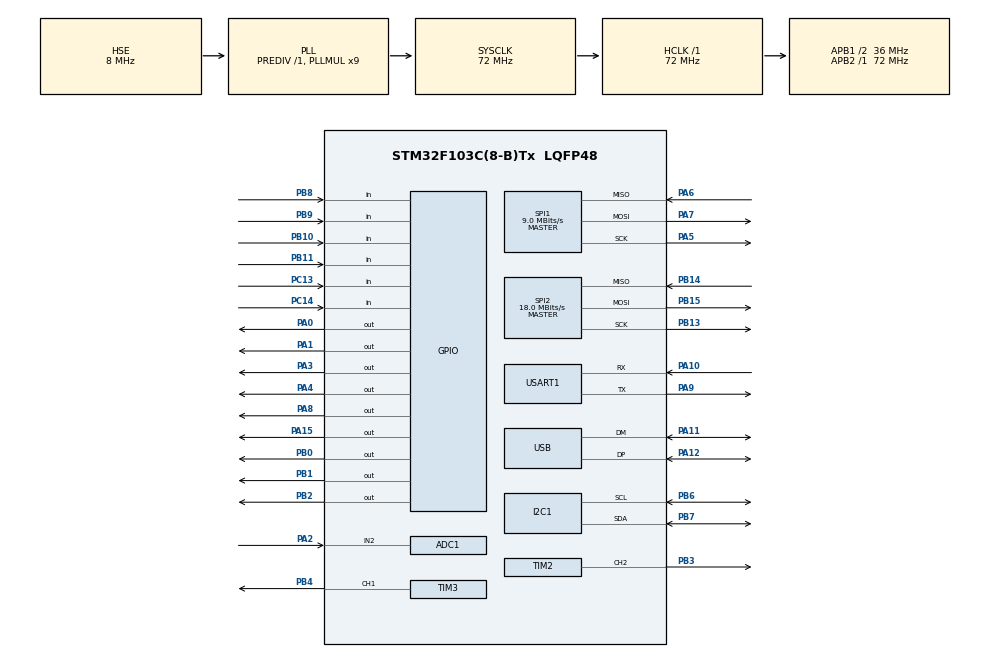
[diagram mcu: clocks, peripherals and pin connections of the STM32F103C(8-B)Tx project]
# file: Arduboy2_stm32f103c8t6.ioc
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ADC1.Channel-4\#ChannelRegularConversion=ADC_CHANNEL_2
ADC1.NbrOfConversionFlag=1
ADC1.Rank-4\#ChannelRegularConversion=1
ADC1.SamplingTime-4\#ChannelRegularConversion=ADC_SAMPLETIME_1CYCLE_5
ADC1.master=1
Mcu.Family=STM32F1
Mcu.Name=STM32F103C(8-B)Tx
Mcu.Package=LQFP48
NVIC.PriorityGroup=NVIC_PRIORITYGROUP_4
NVIC.TIM1_UP_IRQn=true\:0\:0\:false\:false\:true\:true\:true\:true
NVIC.TIM4_IRQn=true\:0\:0\:false\:false\:true\:true\:true\:true
PA0-WKUP.Signal=GPIO_Output
PA1.Signal=GPIO_Output
PA10.Mode=Asynchronous
PA10.Signal=USART1_RX
PA11.Mode=Device
PA11.Signal=USB_DM
PA12.Mode=Device
PA12.Signal=USB_DP
PA13.Mode=Serial_Wire
PA13.Signal=SYS_JTMS-SWDIO
PA14.Mode=Serial_Wire
PA14.Signal=SYS_JTCK-SWCLK
PA15.Signal=GPIO_Output
PA2.Signal=ADCx_IN2
PA3.Signal=GPIO_Output
PA4.Signal=GPIO_Output
PA5.Mode=Full_Duplex_Master
PA5.Signal=SPI1_SCK
PA6.Mode=Full_Duplex_Master
PA6.Signal=SPI1_MISO
PA7.Mode=Full_Duplex_Master
PA7.Signal=SPI1_MOSI
PA8.Signal=GPIO_Output
PA9.Mode=Asynchronous
PA9.Signal=USART1_TX
PB0.Signal=GPIO_Output
PB1.Signal=GPIO_Output
PB10.Signal=GPIO_Input
PB11.Signal=GPIO_Input
PB13.Mode=Full_Duplex_Master
PB13.Signal=SPI2_SCK
PB14.Mode=Full_Duplex_Master
PB14.Signal=SPI2_MISO
PB15.Mode=Full_Duplex_Master
PB15.Signal=SPI2_MOSI
PB2.Signal=GPIO_Output
PB3.Signal=S_TIM2_CH2
PB4.Signal=S_TIM3_CH1
PB6.Mode=I2C
PB6.Signal=I2C1_SCL
PB7.Mode=I2C
PB7.Signal=I2C1_SDA
PB8.Signal=GPIO_Input
PB9.Signal=GPIO_Input
PC13-TAMPER-RTC.Signal=GPIO_Input
PC14-OSC32_IN.Signal=GPIO_Input
PD0-OSC_IN.Mode=HSE-External-Oscillator
PD0-OSC_IN.Signal=RCC_OSC_IN
PD1-OSC_OUT.Mode=HSE-External-Oscillator
PD1-OSC_OUT.Signal=RCC_OSC_OUT
ProjectManager.HeapSize=0x200
ProjectManager.StackSize=0x400
ProjectManager.TargetToolchain=Makefile
RCC.ADCPresc=RCC_ADCPCLK2_DIV8
RCC.AHBFreq_Value=72000000
RCC.APB1CLKDivider=RCC_HCLK_DIV2
RCC.APB1Freq_Value=36000000
RCC.APB1TimFreq_Value=72000000
RCC.APB2Freq_Value=72000000
RCC.APB2TimFreq_Value=72000000
RCC.HCLKFreq_Value=72000000
RCC.PLLMUL=RCC_PLL_MUL9
RCC.SYSCLKFreq_VALUE=72000000
RCC.SYSCLKSource=RCC_SYSCLKSOURCE_PLLCLK
RCC.USBFreq_Value=48000000
RCC.USBPrescaler=RCC_USBCLKSOURCE_PLL_DIV1_5
SH.ADCx_IN2.0=ADC1_IN2,IN2
SH.S_TIM2_CH2.0=TIM2_CH2,PWM Generation2 CH2
SH.S_TIM3_CH1.0=TIM3_CH1,PWM Generation1 CH1
SPI1.BaudRatePrescaler=SPI_BAUDRATEPRESCALER_8
SPI1.CalculateBaudRate=9.0 MBits/s
SPI1.Direction=SPI_DIRECTION_2LINES
SPI1.Mode=SPI_MODE_MASTER
SPI1.VirtualType=VM_MASTER
SPI2.BaudRatePrescaler=SPI_BAUDRATEPRESCALER_2
SPI2.CalculateBaudRate=18.0 MBits/s
SPI2.Direction=SPI_DIRECTION_2LINES
SPI2.Mode=SPI_MODE_MASTER
SPI2.VirtualType=VM_MASTER
TIM1.AutoReloadPreload=TIM_AUTORELOAD_PRELOAD_ENABLE
TIM1.Period=62500
TIM1.Prescaler=1152-1
TIM2.AutoReloadPreload=TIM_AUTORELOAD_PRELOAD_ENABLE
TIM2.Channel-PWM\ Generation2\ CH2=TIM_CHANNEL_2
TIM2.Period=500
TIM2.Prescaler=71
TIM3.AutoReloadPreload=TIM_AUTORELOAD_PRELOAD_ENABLE
TIM3.Channel-PWM\ Generation1\ CH1=TIM_CHANNEL_1
TIM3.Period=500
TIM3.Prescaler=71
TIM4.AutoReloadPreload=TIM_AUTORELOAD_PRELOAD_ENABLE
TIM4.Period=62500
TIM4.Prescaler=1152-1
USART1.VirtualMode=VM_ASYNC
VP_TIM1_VS_ClockSourceINT.Mode=Internal
VP_TIM2_VS_ClockSourceINT.Mode=Internal
VP_TIM3_VS_ClockSourceINT.Mode=Internal
VP_TIM4_VS_ClockSourceINT.Mode=Internal
board=custom

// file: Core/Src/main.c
/* USER CODE BEGIN Header */
/**
  ******************************************************************************
  * @file           : main.c
  * @brief          : Main program body
  ******************************************************************************
  * @attention
  *
  * Copyright (c) 2024 STMicroelectronics.
  * All rights reserved.
  *
  * This software is licensed under terms that can be found in the LICENSE file
  * in the root directory of this software component.
  * If no LICENSE file comes with this software, it is provided AS-IS.
  *
  ******************************************************************************
  */
/* USER CODE END Header */
#include "main.h"

/* USER CODE BEGIN Includes */
#include <stdio.h>
#include "Arduboy2_app.h"
/* USER CODE END Includes */

ADC_HandleTypeDef hadc1;

I2C_HandleTypeDef hi2c1;

SPI_HandleTypeDef hspi1;
SPI_HandleTypeDef hspi2;

TIM_HandleTypeDef htim1;
TIM_HandleTypeDef htim2;
TIM_HandleTypeDef htim3;
TIM_HandleTypeDef htim4;

UART_HandleTypeDef huart1;

PCD_HandleTypeDef hpcd_USB_FS;

void SystemClock_Config(void);
static void MX_GPIO_Init(void);
static void MX_SPI1_Init(void);
static void MX_USART1_UART_Init(void);
static void MX_USB_PCD_Init(void);
static void MX_I2C1_Init(void);
static void MX_SPI2_Init(void);
static void MX_TIM2_Init(void);
static void MX_ADC1_Init(void);
static void MX_TIM3_Init(void);
static void MX_TIM1_Init(void);
static void MX_TIM4_Init(void);

/* USER CODE BEGIN 0 */
int _write (int fd, char *pBuffer, int size)
{
    HAL_UART_Transmit(&huart1, (uint8_t *) pBuffer, size, 0xFFFF);
    return size;
}
/* USER CODE END 0 */

int main(void)
{

  /* MCU Configuration--------------------------------------------------------*/

  /* Reset of all peripherals, Initializes the Flash interface and the Systick. */
  HAL_Init();

  /* Configure the system clock */
  SystemClock_Config();

  /* Initialize all configured peripherals */
  MX_GPIO_Init();
  MX_SPI1_Init();
  MX_USART1_UART_Init();
  MX_USB_PCD_Init();
  MX_I2C1_Init();
  MX_SPI2_Init();
  MX_TIM2_Init();
  MX_ADC1_Init();
  MX_TIM3_Init();
  MX_TIM1_Init();
  MX_TIM4_Init();
  /* USER CODE BEGIN 2 */
  arduboy2_app_init();
  /* USER CODE END 2 */

  /* Infinite loop */
  while (1)
  {

    /* USER CODE BEGIN 3 */
    HAL_Delay(1000);
    // pwm = (pwm >= 500) ? 0 : (pwm + 50);
  }
  /* USER CODE END 3 */
}

void SystemClock_Config(void)
{
  RCC_OscInitTypeDef RCC_OscInitStruct = {0};
  RCC_ClkInitTypeDef RCC_ClkInitStruct = {0};
  RCC_PeriphCLKInitTypeDef PeriphClkInit = {0};

  /** Initializes the RCC Oscillators according to the specified parameters
  * in the RCC_OscInitTypeDef structure.
  */
  RCC_OscInitStruct.OscillatorType = RCC_OSCILLATORTYPE_HSE;
  RCC_OscInitStruct.HSEState = RCC_HSE_ON;
  RCC_OscInitStruct.HSEPredivValue = RCC_HSE_PREDIV_DIV1;
  RCC_OscInitStruct.HSIState = RCC_HSI_ON;
  RCC_OscInitStruct.PLL.PLLState = RCC_PLL_ON;
  RCC_OscInitStruct.PLL.PLLSource = RCC_PLLSOURCE_HSE;
  RCC_OscInitStruct.PLL.PLLMUL = RCC_PLL_MUL9;
  if (HAL_RCC_OscConfig(&RCC_OscInitStruct) != HAL_OK)
  {
    Error_Handler();
  }

  /** Initializes the CPU, AHB and APB buses clocks
  */
  RCC_ClkInitStruct.ClockType = RCC_CLOCKTYPE_HCLK|RCC_CLOCKTYPE_SYSCLK
                              |RCC_CLOCKTYPE_PCLK1|RCC_CLOCKTYPE_PCLK2;
  RCC_ClkInitStruct.SYSCLKSource = RCC_SYSCLKSOURCE_PLLCLK;
  RCC_ClkInitStruct.AHBCLKDivider = RCC_SYSCLK_DIV1;
  RCC_ClkInitStruct.APB1CLKDivider = RCC_HCLK_DIV2;
  RCC_ClkInitStruct.APB2CLKDivider = RCC_HCLK_DIV1;

  if (HAL_RCC_ClockConfig(&RCC_ClkInitStruct, FLASH_LATENCY_2) != HAL_OK)
  {
    Error_Handler();
  }
  PeriphClkInit.PeriphClockSelection = RCC_PERIPHCLK_ADC|RCC_PERIPHCLK_USB;
  PeriphClkInit.AdcClockSelection = RCC_ADCPCLK2_DIV8;
  PeriphClkInit.UsbClockSelection = RCC_USBCLKSOURCE_PLL_DIV1_5;
  if (HAL_RCCEx_PeriphCLKConfig(&PeriphClkInit) != HAL_OK)
  {
    Error_Handler();
  }
}

static void MX_ADC1_Init(void)
{

  ADC_ChannelConfTypeDef sConfig = {0};

  /** Common config
  */
  hadc1.Instance = ADC1;
  hadc1.Init.ScanConvMode = ADC_SCAN_DISABLE;
  hadc1.Init.ContinuousConvMode = DISABLE;
  hadc1.Init.DiscontinuousConvMode = DISABLE;
  hadc1.Init.ExternalTrigConv = ADC_SOFTWARE_START;
  hadc1.Init.DataAlign = ADC_DATAALIGN_RIGHT;
  hadc1.Init.NbrOfConversion = 1;
  if (HAL_ADC_Init(&hadc1) != HAL_OK)
  {
    Error_Handler();
  }

  /** Configure Regular Channel
  */
  sConfig.Channel = ADC_CHANNEL_2;
  sConfig.Rank = ADC_REGULAR_RANK_1;
  sConfig.SamplingTime = ADC_SAMPLETIME_1CYCLE_5;
  if (HAL_ADC_ConfigChannel(&hadc1, &sConfig) != HAL_OK)
  {
    Error_Handler();
  }

}

static void MX_I2C1_Init(void)
{

  hi2c1.Instance = I2C1;
  hi2c1.Init.ClockSpeed = 100000;
  hi2c1.Init.DutyCycle = I2C_DUTYCYCLE_2;
  hi2c1.Init.OwnAddress1 = 0;
  hi2c1.Init.AddressingMode = I2C_ADDRESSINGMODE_7BIT;
  hi2c1.Init.DualAddressMode = I2C_DUALADDRESS_DISABLE;
  hi2c1.Init.OwnAddress2 = 0;
  hi2c1.Init.GeneralCallMode = I2C_GENERALCALL_DISABLE;
  hi2c1.Init.NoStretchMode = I2C_NOSTRETCH_DISABLE;
  if (HAL_I2C_Init(&hi2c1) != HAL_OK)
  {
    Error_Handler();
  }

}

static void MX_SPI1_Init(void)
{

  /* SPI1 parameter configuration*/
  hspi1.Instance = SPI1;
  hspi1.Init.Mode = SPI_MODE_MASTER;
  hspi1.Init.Direction = SPI_DIRECTION_2LINES;
  hspi1.Init.DataSize = SPI_DATASIZE_8BIT;
  hspi1.Init.CLKPolarity = SPI_POLARITY_LOW;
  hspi1.Init.CLKPhase = SPI_PHASE_1EDGE;
  hspi1.Init.NSS = SPI_NSS_SOFT;
  hspi1.Init.BaudRatePrescaler = SPI_BAUDRATEPRESCALER_8;
  hspi1.Init.FirstBit = SPI_FIRSTBIT_MSB;
  hspi1.Init.TIMode = SPI_TIMODE_DISABLE;
  hspi1.Init.CRCCalculation = SPI_CRCCALCULATION_DISABLE;
  hspi1.Init.CRCPolynomial = 10;
  if (HAL_SPI_Init(&hspi1) != HAL_OK)
  {
    Error_Handler();
  }

}

static void MX_SPI2_Init(void)
{

  /* SPI2 parameter configuration*/
  hspi2.Instance = SPI2;
  hspi2.Init.Mode = SPI_MODE_MASTER;
  hspi2.Init.Direction = SPI_DIRECTION_2LINES;
  hspi2.Init.DataSize = SPI_DATASIZE_8BIT;
  hspi2.Init.CLKPolarity = SPI_POLARITY_LOW;
  hspi2.Init.CLKPhase = SPI_PHASE_1EDGE;
  hspi2.Init.NSS = SPI_NSS_SOFT;
  hspi2.Init.BaudRatePrescaler = SPI_BAUDRATEPRESCALER_2;
  hspi2.Init.FirstBit = SPI_FIRSTBIT_MSB;
  hspi2.Init.TIMode = SPI_TIMODE_DISABLE;
  hspi2.Init.CRCCalculation = SPI_CRCCALCULATION_DISABLE;
  hspi2.Init.CRCPolynomial = 10;
  if (HAL_SPI_Init(&hspi2) != HAL_OK)
  {
    Error_Handler();
  }

}

static void MX_TIM1_Init(void)
{

  TIM_ClockConfigTypeDef sClockSourceConfig = {0};
  TIM_MasterConfigTypeDef sMasterConfig = {0};

  htim1.Instance = TIM1;
  htim1.Init.Prescaler = 1152-1;
  htim1.Init.CounterMode = TIM_COUNTERMODE_UP;
  htim1.Init.Period = 62500;
  htim1.Init.ClockDivision = TIM_CLOCKDIVISION_DIV1;
  htim1.Init.RepetitionCounter = 0;
  htim1.Init.AutoReloadPreload = TIM_AUTORELOAD_PRELOAD_ENABLE;
  if (HAL_TIM_Base_Init(&htim1) != HAL_OK)
  {
    Error_Handler();
  }
  sClockSourceConfig.ClockSource = TIM_CLOCKSOURCE_INTERNAL;
  if (HAL_TIM_ConfigClockSource(&htim1, &sClockSourceConfig) != HAL_OK)
  {
    Error_Handler();
  }
  sMasterConfig.MasterOutputTrigger = TIM_TRGO_RESET;
  sMasterConfig.MasterSlaveMode = TIM_MASTERSLAVEMODE_DISABLE;
  if (HAL_TIMEx_MasterConfigSynchronization(&htim1, &sMasterConfig) != HAL_OK)
  {
    Error_Handler();
  }

}

static void MX_TIM2_Init(void)
{

  TIM_ClockConfigTypeDef sClockSourceConfig = {0};
  TIM_MasterConfigTypeDef sMasterConfig = {0};
  TIM_OC_InitTypeDef sConfigOC = {0};

  htim2.Instance = TIM2;
  htim2.Init.Prescaler = 71;
  htim2.Init.CounterMode = TIM_COUNTERMODE_UP;
  htim2.Init.Period = 500;
  htim2.Init.ClockDivision = TIM_CLOCKDIVISION_DIV1;
  htim2.Init.AutoReloadPreload = TIM_AUTORELOAD_PRELOAD_ENABLE;
  if (HAL_TIM_Base_Init(&htim2) != HAL_OK)
  {
    Error_Handler();
  }
  sClockSourceConfig.ClockSource = TIM_CLOCKSOURCE_INTERNAL;
  if (HAL_TIM_ConfigClockSource(&htim2, &sClockSourceConfig) != HAL_OK)
  {
    Error_Handler();
  }
  if (HAL_TIM_PWM_Init(&htim2) != HAL_OK)
  {
    Error_Handler();
  }
  sMasterConfig.MasterOutputTrigger = TIM_TRGO_RESET;
  sMasterConfig.MasterSlaveMode = TIM_MASTERSLAVEMODE_DISABLE;
  if (HAL_TIMEx_MasterConfigSynchronization(&htim2, &sMasterConfig) != HAL_OK)
  {
    Error_Handler();
  }
  sConfigOC.OCMode = TIM_OCMODE_PWM1;
  sConfigOC.Pulse = 0;
  sConfigOC.OCPolarity = TIM_OCPOLARITY_HIGH;
  sConfigOC.OCFastMode = TIM_OCFAST_DISABLE;
  if (HAL_TIM_PWM_ConfigChannel(&htim2, &sConfigOC, TIM_CHANNEL_2) != HAL_OK)
  {
    Error_Handler();
  }
  HAL_TIM_MspPostInit(&htim2);

}

static void MX_TIM3_Init(void)
{

  TIM_ClockConfigTypeDef sClockSourceConfig = {0};
  TIM_MasterConfigTypeDef sMasterConfig = {0};
  TIM_OC_InitTypeDef sConfigOC = {0};

  htim3.Instance = TIM3;
  htim3.Init.Prescaler = 71;
  htim3.Init.CounterMode = TIM_COUNTERMODE_UP;
  htim3.Init.Period = 500;
  htim3.Init.ClockDivision = TIM_CLOCKDIVISION_DIV1;
  htim3.Init.AutoReloadPreload = TIM_AUTORELOAD_PRELOAD_ENABLE;
  if (HAL_TIM_Base_Init(&htim3) != HAL_OK)
  {
    Error_Handler();
  }
  sClockSourceConfig.ClockSource = TIM_CLOCKSOURCE_INTERNAL;
  if (HAL_TIM_ConfigClockSource(&htim3, &sClockSourceConfig) != HAL_OK)
  {
    Error_Handler();
  }
  if (HAL_TIM_PWM_Init(&htim3) != HAL_OK)
  {
    Error_Handler();
  }
  sMasterConfig.MasterOutputTrigger = TIM_TRGO_RESET;
  sMasterConfig.MasterSlaveMode = TIM_MASTERSLAVEMODE_DISABLE;
  if (HAL_TIMEx_MasterConfigSynchronization(&htim3, &sMasterConfig) != HAL_OK)
  {
    Error_Handler();
  }
  sConfigOC.OCMode = TIM_OCMODE_PWM1;
  sConfigOC.Pulse = 0;
  sConfigOC.OCPolarity = TIM_OCPOLARITY_HIGH;
  sConfigOC.OCFastMode = TIM_OCFAST_DISABLE;
  if (HAL_TIM_PWM_ConfigChannel(&htim3, &sConfigOC, TIM_CHANNEL_1) != HAL_OK)
  {
    Error_Handler();
  }
  HAL_TIM_MspPostInit(&htim3);

}

static void MX_TIM4_Init(void)
{

  TIM_ClockConfigTypeDef sClockSourceConfig = {0};
  TIM_MasterConfigTypeDef sMasterConfig = {0};

  htim4.Instance = TIM4;
  htim4.Init.Prescaler = 1152-1;
  htim4.Init.CounterMode = TIM_COUNTERMODE_UP;
  htim4.Init.Period = 62500;
  htim4.Init.ClockDivision = TIM_CLOCKDIVISION_DIV1;
  htim4.Init.AutoReloadPreload = TIM_AUTORELOAD_PRELOAD_ENABLE;
  if (HAL_TIM_Base_Init(&htim4) != HAL_OK)
  {
    Error_Handler();
  }
  sClockSourceConfig.ClockSource = TIM_CLOCKSOURCE_INTERNAL;
  if (HAL_TIM_ConfigClockSource(&htim4, &sClockSourceConfig) != HAL_OK)
  {
    Error_Handler();
  }
  sMasterConfig.MasterOutputTrigger = TIM_TRGO_RESET;
  sMasterConfig.MasterSlaveMode = TIM_MASTERSLAVEMODE_DISABLE;
  if (HAL_TIMEx_MasterConfigSynchronization(&htim4, &sMasterConfig) != HAL_OK)
  {
    Error_Handler();
  }

}

static void MX_USART1_UART_Init(void)
{

  huart1.Instance = USART1;
  huart1.Init.BaudRate = 115200;
  huart1.Init.WordLength = UART_WORDLENGTH_8B;
  huart1.Init.StopBits = UART_STOPBITS_1;
  huart1.Init.Parity = UART_PARITY_NONE;
  huart1.Init.Mode = UART_MODE_TX_RX;
  huart1.Init.HwFlowCtl = UART_HWCONTROL_NONE;
  huart1.Init.OverSampling = UART_OVERSAMPLING_16;
  if (HAL_UART_Init(&huart1) != HAL_OK)
  {
    Error_Handler();
  }

}

static void MX_USB_PCD_Init(void)
{

  hpcd_USB_FS.Instance = USB;
  hpcd_USB_FS.Init.dev_endpoints = 8;
  hpcd_USB_FS.Init.speed = PCD_SPEED_FULL;
  hpcd_USB_FS.Init.low_power_enable = DISABLE;
  hpcd_USB_FS.Init.lpm_enable = DISABLE;
  hpcd_USB_FS.Init.battery_charging_enable = DISABLE;
  if (HAL_PCD_Init(&hpcd_USB_FS) != HAL_OK)
  {
    Error_Handler();
  }

}

static void MX_GPIO_Init(void)
{
  GPIO_InitTypeDef GPIO_InitStruct = {0};

  /* GPIO Ports Clock Enable */
  __HAL_RCC_GPIOC_CLK_ENABLE();
  __HAL_RCC_GPIOD_CLK_ENABLE();
  __HAL_RCC_GPIOA_CLK_ENABLE();
  __HAL_RCC_GPIOB_CLK_ENABLE();

  /*Configure GPIO pin Output Level */
  HAL_GPIO_WritePin(GPIOA, GPIO_PIN_0|GPIO_PIN_1|GPIO_PIN_3|GPIO_PIN_4
                          |GPIO_PIN_8|GPIO_PIN_15, GPIO_PIN_RESET);

  /*Configure GPIO pin Output Level */
  HAL_GPIO_WritePin(GPIOB, GPIO_PIN_0|GPIO_PIN_1|GPIO_PIN_2, GPIO_PIN_RESET);

  /*Configure GPIO pins : PC13 PC14 */
  GPIO_InitStruct.Pin = GPIO_PIN_13|GPIO_PIN_14;
  GPIO_InitStruct.Mode = GPIO_MODE_INPUT;
  GPIO_InitStruct.Pull = GPIO_NOPULL;
  HAL_GPIO_Init(GPIOC, &GPIO_InitStruct);

  /*Configure GPIO pins : PA0 PA1 PA3 PA4
                           PA8 PA15 */
  GPIO_InitStruct.Pin = GPIO_PIN_0|GPIO_PIN_1|GPIO_PIN_3|GPIO_PIN_4
                          |GPIO_PIN_8|GPIO_PIN_15;
  GPIO_InitStruct.Mode = GPIO_MODE_OUTPUT_PP;
  GPIO_InitStruct.Pull = GPIO_NOPULL;
  GPIO_InitStruct.Speed = GPIO_SPEED_FREQ_LOW;
  HAL_GPIO_Init(GPIOA, &GPIO_InitStruct);

  /*Configure GPIO pins : PB0 PB1 PB2 */
  GPIO_InitStruct.Pin = GPIO_PIN_0|GPIO_PIN_1|GPIO_PIN_2;
  GPIO_InitStruct.Mode = GPIO_MODE_OUTPUT_PP;
  GPIO_InitStruct.Pull = GPIO_NOPULL;
  GPIO_InitStruct.Speed = GPIO_SPEED_FREQ_LOW;
  HAL_GPIO_Init(GPIOB, &GPIO_InitStruct);

  /*Configure GPIO pins : PB10 PB11 PB8 PB9 */
  GPIO_InitStruct.Pin = GPIO_PIN_10|GPIO_PIN_11|GPIO_PIN_8|GPIO_PIN_9;
  GPIO_InitStruct.Mode = GPIO_MODE_INPUT;
  GPIO_InitStruct.Pull = GPIO_NOPULL;
  HAL_GPIO_Init(GPIOB, &GPIO_InitStruct);

}

void Error_Handler(void)
{
  __disable_irq();
  while (1)
  {
  }
}
